# f29h85x_esm_cpu_regs register map
Vendor: Texas Instruments
Peripheral module from a debugger description file (folder C29).
Registers are 32-bit, read-write, no defined reset value unless marked. A register's access mark holds for its fields unless they carry their own. Offsets are as the file gives them; lines under a group give offsets from that group; [hi:lo] are bit positions; {n}, {i} and the like mark numbered series; 'fields as' and 'values as' point back to an identical list; <NAME> marks a mode.

## ESM_CPU_REGS — ESM CPU Registers
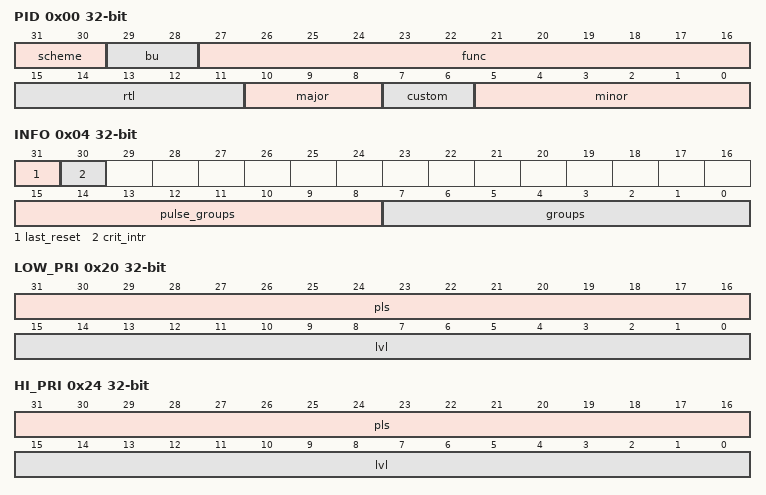
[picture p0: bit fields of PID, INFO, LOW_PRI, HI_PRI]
0x00 PID ro — Revision Register
  [31:30] scheme, [29:28] bu, [27:16] func, [15:11] rtl, [10:8] major, [7:6] custom, [5:0] minor
0x04 INFO ro
  [31] last_reset, [30] crit_intr, [15:8] pulse_groups, [7:0] groups
0x08 EN — Global Enable Register
  [3:0] key
0x0C SFT_RST — Global Soft Reset Register
  [3:0] key
0x20 LOW_PRI ro — Low Priority Prioritized Register
  [31:16] pls, [15:0] lvl
0x24 HI_PRI ro — High Priority Prioritized Register
  [31:16] pls, [15:0] lvl
0x28 LOW ro — Low Priority Interrupt Status Register
  [31:0] sts
0x2C HI ro — High Priority Interrupt Status Register
  [31:0] sts
0x30 EOI — EOI Interrupt Register
  [10:0] key
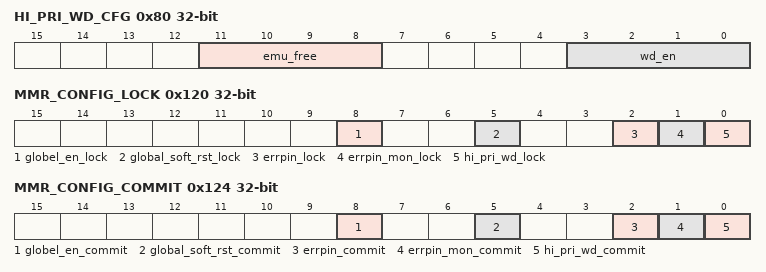
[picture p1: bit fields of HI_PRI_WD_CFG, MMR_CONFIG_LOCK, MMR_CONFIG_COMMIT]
0x80 HI_PRI_WD_CFG — High Priority Watchdog Config Register
  [11:8] emu_free, [3:0] wd_en
0x84 HI_PRI_WD_CNTR ro — High Priority Watchdog Counter Value Register
  [31:0] count
0x88 HI_PRI_WD_CNTR_PRE — High Priority Watchdog Pre-Load Register
  [31:0] count
0x8C HI_PRI_WD_INTR_SET — High Priority Watchdog Interrupt Status/Set Register
  [0] val
0x90 HI_PRI_WD_INTR_CLR — High Priority Watchdog Interrupt Status/Clear Register
  [0] val
0x100 GROUP_N_LOCK — Group N Interrupt Lock Register
0x104 GROUP_N_COMMIT — Group N Interrupt Commit Register
0x118 CRI_PRI_INFLUENCE_LOCK — Critical Prioirty Interrupt Influence Lock Register
0x11C CRI_PRI_INFLUENCE_COMMIT — Critical Priority Interrupt Influence Lock Register
0x120 MMR_CONFIG_LOCK
  [8] globel_en_lock, [5] global_soft_rst_lock, [2] errpin_lock, [1] errpin_mon_lock, [0] hi_pri_wd_lock
0x124 MMR_CONFIG_COMMIT
  [8] globel_en_commit, [5] global_soft_rst_commit, [2] errpin_commit, [1] errpin_mon_commit, [0] hi_pri_wd_commit
{0x400+0x20*i} ERR_GRP[{i}] (i=0..7) group
  0x00 RAW — Error Group N Event Raw Status/Set Register
    [31:0] sts
  0x04 STS — Error Group N Interrupt Enable Status/Clear Register
    [31:0] msk
  0x08 INTR_EN_SET — Error Group N Interrupt Enable Set Register
    [31:0] msk
  0x0C INTR_EN_CLR — Error Group N Interrupt Enabled Clear Register
    [31:0] msk
  0x10 INT_PRIO — Error Group N Interrupt Priority Register
    [31:0] msk
{0x800+0x20*i} ERR_EXT_GRP[{i}] (i=0..7) group
  0x00 CRIT_EN_SET — Error Group N Critical Priority Interrupt Influence Set Register
    [31:0] msk
  0x04 CRIT_EN_CLR — Error Group N Critical Priority Interrupt Influence Clear Register
    [31:0] msk
